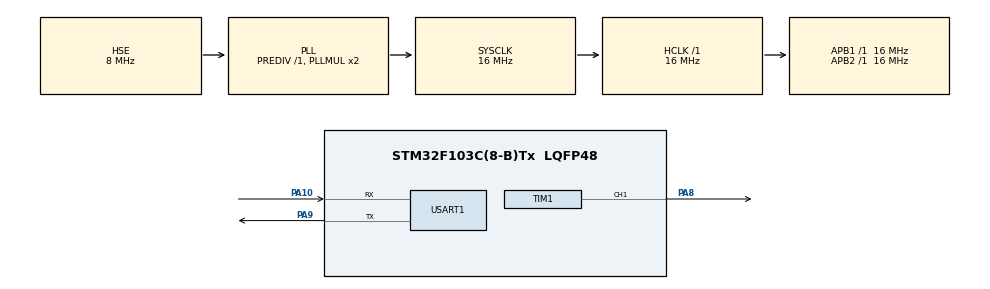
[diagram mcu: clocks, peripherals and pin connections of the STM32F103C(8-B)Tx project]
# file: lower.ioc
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Dma.Request0=USART1_RX
Dma.Request1=USART1_TX
Dma.USART1_RX.0.Direction=DMA_PERIPH_TO_MEMORY
Dma.USART1_RX.0.Instance=DMA1_Channel5
Dma.USART1_RX.0.MemDataAlignment=DMA_MDATAALIGN_BYTE
Dma.USART1_RX.0.MemInc=DMA_MINC_ENABLE
Dma.USART1_RX.0.Mode=DMA_NORMAL
Dma.USART1_RX.0.PeriphDataAlignment=DMA_PDATAALIGN_BYTE
Dma.USART1_RX.0.PeriphInc=DMA_PINC_DISABLE
Dma.USART1_RX.0.Priority=DMA_PRIORITY_LOW
Dma.USART1_TX.1.Direction=DMA_MEMORY_TO_PERIPH
Dma.USART1_TX.1.Instance=DMA1_Channel4
Dma.USART1_TX.1.MemDataAlignment=DMA_MDATAALIGN_BYTE
Dma.USART1_TX.1.MemInc=DMA_MINC_ENABLE
Dma.USART1_TX.1.Mode=DMA_NORMAL
Dma.USART1_TX.1.PeriphDataAlignment=DMA_PDATAALIGN_BYTE
Dma.USART1_TX.1.PeriphInc=DMA_PINC_DISABLE
Dma.USART1_TX.1.Priority=DMA_PRIORITY_LOW
FREERTOS.Tasks01=main_app,24,128,mainApp,Default,NULL,Dynamic,NULL,NULL
Mcu.Family=STM32F1
Mcu.Name=STM32F103C(8-B)Tx
Mcu.Package=LQFP48
NVIC.DMA1_Channel4_IRQn=true\:5\:0\:false\:false\:true\:true\:false\:true
NVIC.DMA1_Channel5_IRQn=true\:5\:0\:false\:false\:true\:true\:false\:true
NVIC.PriorityGroup=NVIC_PRIORITYGROUP_4
NVIC.TIM1_CC_IRQn=true\:5\:0\:false\:false\:true\:true\:true\:true
NVIC.TIM4_IRQn=true\:0\:0\:false\:false\:true\:false\:false\:true
NVIC.TimeBase=TIM4_IRQn
NVIC.TimeBaseIP=TIM4
NVIC.USART1_IRQn=true\:5\:0\:false\:false\:true\:true\:true\:true
PA10.Mode=Asynchronous
PA10.Signal=USART1_RX
PA13.Mode=Serial_Wire
PA13.Signal=SYS_JTMS-SWDIO
PA14.Mode=Serial_Wire
PA14.Signal=SYS_JTCK-SWCLK
PA8.Signal=S_TIM1_CH1
PA9.Mode=Asynchronous
PA9.Signal=USART1_TX
PD0-OSC_IN.Mode=HSE-External-Oscillator
PD0-OSC_IN.Signal=RCC_OSC_IN
PD1-OSC_OUT.Mode=HSE-External-Oscillator
PD1-OSC_OUT.Signal=RCC_OSC_OUT
ProjectManager.HeapSize=0x200
ProjectManager.StackSize=0x400
ProjectManager.TargetToolchain=STM32CubeIDE
RCC.AHBFreq_Value=16000000
RCC.APB1Freq_Value=16000000
RCC.APB1TimFreq_Value=16000000
RCC.APB2Freq_Value=16000000
RCC.APB2TimFreq_Value=16000000
RCC.HCLKFreq_Value=16000000
RCC.PLLSourceVirtual=RCC_PLLSOURCE_HSE
RCC.SYSCLKFreq_VALUE=16000000
RCC.SYSCLKSource=RCC_SYSCLKSOURCE_PLLCLK
RCC.USBFreq_Value=16000000
SH.S_TIM1_CH1.0=TIM1_CH1,Output Compare1 CH1
TIM1.Channel-Output\ Compare1\ CH1=TIM_CHANNEL_1
TIM1.OCMode_1=TIM_OCMODE_TOGGLE
USART1.VirtualMode=VM_ASYNC
VP_FREERTOS_VS_CMSIS_V2.Mode=CMSIS_V2
VP_SYS_VS_tim4.Mode=TIM4
board=custom

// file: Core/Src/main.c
/* USER CODE BEGIN Header */
/**
  ******************************************************************************
  * @file           : main.c
  * @brief          : Main program body
  ******************************************************************************
  * @attention
  *
  * <h2><center>&copy; Copyright (c) 2020 STMicroelectronics.
  * All rights reserved.</center></h2>
  *
  * This software component is licensed by ST under BSD 3-Clause license,
  * the "License"; You may not use this file except in compliance with the
  * License. You may obtain a copy of the License at:
  *                        opensource.org/licenses/BSD-3-Clause
  *
  ******************************************************************************
  */
/* USER CODE END Header */

#include "main.h"
#include "cmsis_os.h"
#include "dma.h"
#include "tim.h"
#include "usart.h"
#include "gpio.h"

/* USER CODE BEGIN Includes */
#include "../../Devices/stepper.h"
/* USER CODE END Includes */

/* USER CODE BEGIN PD */
//typedef void (*pTimItHandler)(void *params, TIM_HandleTypeDef *htim);
//pTimItHandler implTimItHandler;
/* USER CODE END PD */

void SystemClock_Config(void);

void MX_FREERTOS_Init(void);

/* USER CODE BEGIN 0 */
Stepper stepper1, stepper2;
Stepper *steppers[2] = {&stepper1, &stepper2};
/* USER CODE END 0 */

int main(void) {
    /* USER CODE BEGIN 1 */
    stepper1.stepper_hardware.timer_name = 1;
    stepper1.cur_steps = 0;
    stepper2.stepper_hardware.timer_name = 2;
    stepper2.cur_steps = 0;
//    implTimItHandler = stepperUpdateSteps;
    uint8_t receive_buff[255];
    /* USER CODE END 1 */

    /* MCU Configuration--------------------------------------------------------*/

    /* Reset of all peripherals, Initializes the Flash interface and the Systick. */
    HAL_Init();

    /* Configure the system clock */
    SystemClock_Config();

    /* Initialize all configured peripherals */
    MX_GPIO_Init();
    MX_DMA_Init();
    MX_TIM1_Init();
    MX_USART1_UART_Init();
    /* USER CODE BEGIN 2 */
    __HAL_UART_ENABLE_IT(&huart1, UART_IT_IDLE);
    HAL_UART_Receive_DMA(&huart1, (uint8_t *) receive_buff, 255);
    /* USER CODE END 2 */
    /* Init scheduler */
    osKernelInitialize();

    /* Call init function for freertos objects (in freertos.c) */
    MX_FREERTOS_Init();

    /* Start scheduler */
    osKernelStart();

    /* We should never get here as control is now taken by the scheduler */

    /* Infinite loop */
    /* USER CODE BEGIN WHILE */
    while (1) {
//        stepperStop(&stepper1);
        /* USER CODE END WHILE */

    }
}

void SystemClock_Config(void) {
    RCC_OscInitTypeDef RCC_OscInitStruct = {0};
    RCC_ClkInitTypeDef RCC_ClkInitStruct = {0};

    /** Initializes the CPU, AHB and APB busses clocks
    */
    RCC_OscInitStruct.OscillatorType = RCC_OSCILLATORTYPE_HSE;
    RCC_OscInitStruct.HSEState = RCC_HSE_ON;
    RCC_OscInitStruct.HSEPredivValue = RCC_HSE_PREDIV_DIV1;
    RCC_OscInitStruct.HSIState = RCC_HSI_ON;
    RCC_OscInitStruct.PLL.PLLState = RCC_PLL_ON;
    RCC_OscInitStruct.PLL.PLLSource = RCC_PLLSOURCE_HSE;
    RCC_OscInitStruct.PLL.PLLMUL = RCC_PLL_MUL2;
    if (HAL_RCC_OscConfig(&RCC_OscInitStruct) != HAL_OK) {
        Error_Handler();
    }
    /** Initializes the CPU, AHB and APB busses clocks
    */
    RCC_ClkInitStruct.ClockType = RCC_CLOCKTYPE_HCLK | RCC_CLOCKTYPE_SYSCLK
                                  | RCC_CLOCKTYPE_PCLK1 | RCC_CLOCKTYPE_PCLK2;
    RCC_ClkInitStruct.SYSCLKSource = RCC_SYSCLKSOURCE_PLLCLK;
    RCC_ClkInitStruct.AHBCLKDivider = RCC_SYSCLK_DIV1;
    RCC_ClkInitStruct.APB1CLKDivider = RCC_HCLK_DIV1;
    RCC_ClkInitStruct.APB2CLKDivider = RCC_HCLK_DIV1;

    if (HAL_RCC_ClockConfig(&RCC_ClkInitStruct, FLASH_LATENCY_0) != HAL_OK) {
        Error_Handler();
    }
}

/* USER CODE BEGIN 4 */
//void testasdf(void)
//{
//	int i =0;
//}

void HAL_TIM_OC_DelayElapsedCallback(TIM_HandleTypeDef *htim) {
    stepperUpdateSteps(steppers, htim);
}
/* USER CODE END 4 */

void HAL_TIM_PeriodElapsedCallback(TIM_HandleTypeDef *htim) {
    if (htim->Instance == TIM4) {
        HAL_IncTick();
    }
}

void Error_Handler(void) {
}

/************************ (C) COPYRIGHT STMicroelectronics *****END OF FILE****/

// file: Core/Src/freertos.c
/* USER CODE BEGIN Header */
/**
  ******************************************************************************
  * File Name          : freertos.c
  * Description        : Code for freertos applications
  ******************************************************************************
  * @attention
  *
  * <h2><center>&copy; Copyright (c) 2020 STMicroelectronics.
  * All rights reserved.</center></h2>
  *
  * This software component is licensed by ST under Ultimate Liberty license
  * SLA0044, the "License"; You may not use this file except in compliance with
  * the License. You may obtain a copy of the License at:
  *                             www.st.com/SLA0044
  *
  ******************************************************************************
  */
/* USER CODE END Header */

#include "FreeRTOS.h"
#include "task.h"
#include "main.h"
#include "cmsis_os.h"

/* USER CODE BEGIN Includes */
#include "../../Apps/main_app.h"
/* USER CODE END Includes */

/* Definitions for main_app */
osThreadId_t main_appHandle;
const osThreadAttr_t main_app_attributes = {
  .name = "main_app",
  .priority = (osPriority_t) osPriorityNormal,
  .stack_size = 128
};

void mainApp(void *argument);

void MX_FREERTOS_Init(void); /* (MISRA C 2004 rule 8.1) */

void MX_FREERTOS_Init(void) {

  /* Create the thread(s) */
  /* creation of main_app */
  main_appHandle = osThreadNew(mainApp, NULL, &main_app_attributes);

}

void mainApp(void *argument)
{
  /* USER CODE BEGIN mainApp */
    main_app_loop();
    /* Infinite loop */
//  for(;;)
//  {
//    osDelay(1);
//  }
  /* USER CODE END mainApp */
}

/************************ (C) COPYRIGHT STMicroelectronics *****END OF FILE****/
